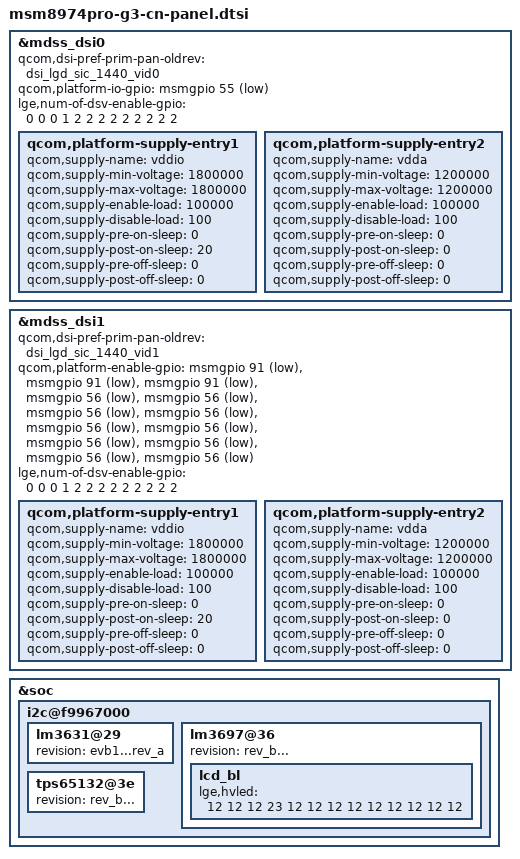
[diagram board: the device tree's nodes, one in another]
/* Copyright (c) 2012, Code Aurora Forum. All rights reserved.
 *
 * This program is free software; you can redistribute it and/or modify
 * it under the terms of the GNU General Public License version 2 and
 * only version 2 as published by the Free Software Foundation.
 *
 * This program is distributed in the hope that it will be useful,
 * but WITHOUT ANY WARRANTY; without even the implied warranty of
 * MERCHANTABILITY or FITNESS FOR A PARTICULAR PURPOSE.  See the
 * GNU General Public License for more details.
 */

&mdss_dsi0 {
	status = "ok";
	/delete-property/ vdd-supply;
	qcom,dsi-pref-prim-pan-oldrev = <&dsi_lgd_sic_1440_vid0>;
	qcom,platform-io-gpio = <&msmgpio 55 1>;
	lge,num-of-dsv-enable-gpio = <
		0 0  // evb1  = 0 ; evb2  = 0
		0 1  // rev_a = 0 ; rev_b = 1
		2 2  // rev_c = 1 ; rev_d = 1
		2 2  // rev_e = 1 ; rev_f = 1
		2 2  // rev_g = 1 ; rev_h = 1
		2 2  // rev_10 = 1; rev_11 = 1
		2     // rev_12 = 1
		>;

	qcom,platform-supply-entry1 {
		qcom,supply-name = "vddio";
		qcom,supply-min-voltage = <1800000>;
		qcom,supply-max-voltage = <1800000>;
		qcom,supply-enable-load = <100000>;
		qcom,supply-disable-load = <100>;
		qcom,supply-pre-on-sleep = <0>;
		qcom,supply-post-on-sleep = <20>;
		qcom,supply-pre-off-sleep = <0>;
		qcom,supply-post-off-sleep = <0>;
	};

	qcom,platform-supply-entry2 {
		qcom,supply-name = "vdda";
		qcom,supply-min-voltage = <1200000>;
		qcom,supply-max-voltage = <1200000>;
		qcom,supply-enable-load = <100000>;
		qcom,supply-disable-load = <100>;
		qcom,supply-pre-on-sleep = <0>;
		qcom,supply-post-on-sleep = <0>;
		qcom,supply-pre-off-sleep = <0>;
		qcom,supply-post-off-sleep = <0>;
	};

	/delete-node/qcom,platform-supply-entry3;

};

&mdss_dsi1 {
	status = "ok";
	/delete-property/ vdd-supply;
	qcom,dsi-pref-prim-pan-oldrev = <&dsi_lgd_sic_1440_vid1>;

	qcom,platform-enable-gpio = <&msmgpio 91 1>, // HW_REV_EVB1
		<&msmgpio 91 1>, // HW_REV_EVB2
		<&msmgpio 91 1>, // HW_REV_A
		<&msmgpio 56 1>, // HW_REV_B
		<&msmgpio 56 1>, // HW_REV_C
		<&msmgpio 56 1>, // HW_REV_D
		<&msmgpio 56 1>, // HW_REV_E
		<&msmgpio 56 1>, // HW_REV_F
		<&msmgpio 56 1>, // HW_REV_G
		<&msmgpio 56 1>, // HW_REV_H
		<&msmgpio 56 1>, // HW_REV_1.0
		<&msmgpio 56 1>, // HW_REV_1.1
		<&msmgpio 56 1>; // HW_REV_1.2

	lge,num-of-dsv-enable-gpio = <
		0 0  // evb1  = 0 ; evb2  = 0
		0 1  // rev_a = 0 ; rev_b = 1
		2 2  // rev_c = 1 ; rev_d = 1
		2 2  // rev_e = 1 ; rev_f = 1
		2 2  // rev_g = 1 ; rev_h = 1
		2 2  // rev_10 = 1; rev_11 = 1
		2     // rev_12 = 1
		>;

	qcom,platform-supply-entry1 {
		qcom,supply-name = "vddio";
		qcom,supply-min-voltage = <1800000>;
		qcom,supply-max-voltage = <1800000>;
		qcom,supply-enable-load = <100000>;
		qcom,supply-disable-load = <100>;
		qcom,supply-pre-on-sleep = <0>;
		qcom,supply-post-on-sleep = <20>;
		qcom,supply-pre-off-sleep = <0>;
		qcom,supply-post-off-sleep = <0>;
	};

	qcom,platform-supply-entry2 {
		qcom,supply-name = "vdda";
		qcom,supply-min-voltage = <1200000>;
		qcom,supply-max-voltage = <1200000>;
		qcom,supply-enable-load = <100000>;
		qcom,supply-disable-load = <100>;
		qcom,supply-pre-on-sleep = <0>;
		qcom,supply-post-on-sleep = <0>;
		qcom,supply-pre-off-sleep = <0>;
		qcom,supply-post-off-sleep = <0>;
	};

	/delete-node/qcom,platform-supply-entry3;
};

&soc {
	i2c@f9967000 {
		lm3631@29{
			status = "ok";
			revision = "evb1...rev_a";
		};
		lm3697@36{
			status = "ok";
			revision = "rev_b...";
			lcd_bl {
				lge,hvled = <
					12 12  // evb1 = hvled1, hvled2 ; evb2 = hvled 1, hvled2
					12 23  // rev_a = hvled 1, hvled2 ; rev_b = hvled 2, hvled3
					12 12  // rev_c = hvled 1, hvled2 ; rev_d = hvled 1, hvled2
					12 12  // rev_e = hvled 1, hvled2 ; rev_f = hvled 1, hvled2
					12 12  // rev_g = hvled 1, hvled2 ; rev_h = hvled 1, hvled2
					12 12  // rev_10 = hvled 1, hvled2 ; rev_11 = hvled 1, hvled2
					12     // rev_12 = hvled 1, hvled2
					>;
			};
		};
		tps65132@3e {
			status = "ok";
			revision = "rev_b...";
		};
     };
};
